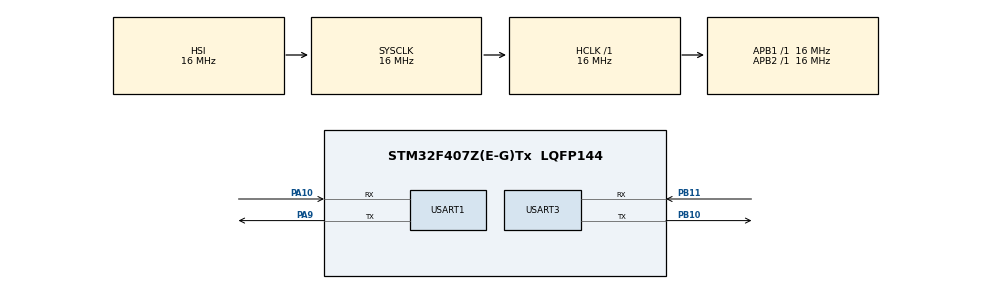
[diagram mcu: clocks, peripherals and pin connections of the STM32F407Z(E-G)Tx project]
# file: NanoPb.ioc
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Mcu.Family=STM32F4
Mcu.Name=STM32F407Z(E-G)Tx
Mcu.Package=LQFP144
NVIC.PriorityGroup=NVIC_PRIORITYGROUP_4
NVIC.TIM1_UP_TIM10_IRQn=true\:15\:0\:false\:false\:true\:false\:true\:true
NVIC.TimeBase=TIM1_UP_TIM10_IRQn
NVIC.TimeBaseIP=TIM1
PA10.Mode=Asynchronous
PA10.Signal=USART1_RX
PA13.Mode=JTAG_4_pins
PA13.Signal=SYS_JTMS-SWDIO
PA14.Mode=JTAG_4_pins
PA14.Signal=SYS_JTCK-SWCLK
PA15.Mode=JTAG_4_pins
PA15.Signal=SYS_JTDI
PA9.Mode=Asynchronous
PA9.Signal=USART1_TX
PB10.Mode=Asynchronous
PB10.Signal=USART3_TX
PB11.Mode=Asynchronous
PB11.Signal=USART3_RX
PB3.Mode=JTAG_4_pins
PB3.Signal=SYS_JTDO-SWO
PH0-OSC_IN.Mode=HSE-External-Oscillator
PH0-OSC_IN.Signal=RCC_OSC_IN
PH1-OSC_OUT.Mode=HSE-External-Oscillator
PH1-OSC_OUT.Signal=RCC_OSC_OUT
ProjectManager.HeapSize=0x2000
ProjectManager.StackSize=0x4000
ProjectManager.TargetToolchain=STM32CubeIDE
RCC.48MHZClocksFreq_Value=48000000
RCC.AHBFreq_Value=16000000
RCC.APB1Freq_Value=16000000
RCC.APB1TimCLKDivider=1
RCC.APB1TimFreq_Value=16000000
RCC.APB2Freq_Value=16000000
RCC.APB2TimCLKDivider=1
RCC.APB2TimFreq_Value=16000000
RCC.CortexFreq_Value=16000000
RCC.HCLKFreq_Value=16000000
RCC.HSE_VALUE=25000000
RCC.HSI_VALUE=16000000
RCC.LSE_VALUE=32768
RCC.SYSCLKFreq_VALUE=16000000
RCC.VCOOutputFreq_Value=192000000
USART1.VirtualMode=VM_ASYNC
USART3.VirtualMode=VM_ASYNC
VP_SYS_VS_tim1.Mode=TIM1
board=custom

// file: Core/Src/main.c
/* USER CODE BEGIN Header */
/**
  ******************************************************************************
  * @file           : main.c
  * @brief          : Main program body
  ******************************************************************************
  * @attention
  *
  * Copyright (c) 2024 STMicroelectronics.
  * All rights reserved.
  *
  * This software is licensed under terms that can be found in the LICENSE file
  * in the root directory of this software component.
  * If no LICENSE file comes with this software, it is provided AS-IS.
  *
  ******************************************************************************
  */
/* USER CODE END Header */
#include "main.h"

/* USER CODE BEGIN Includes */
#include <stdio.h>
#include <pb_encode.h>
#include <pb_decode.h>
#include "simple.pb.h"

/* USER CODE END Includes */

UART_HandleTypeDef huart1;
UART_HandleTypeDef huart3;

void SystemClock_Config(void);
static void MX_GPIO_Init(void);
static void MX_USART1_UART_Init(void);
static void MX_USART3_UART_Init(void);

/* USER CODE BEGIN 0 */
#ifdef __GNUC__
#define PUTCHAR_PROTOTYPE int __io_putchar(int ch)
#else
#define PUTCHAR_PROTOTYPE int fputc(int ch, FILE *f)
#endif

PUTCHAR_PROTOTYPE
{
  HAL_UART_Transmit(&huart3, (uint8_t *)&ch, 1, HAL_MAX_DELAY);
  return ch;
}
/* USER CODE END 0 */

int main(void)
{

  /* MCU Configuration--------------------------------------------------------*/

  /* Reset of all peripherals, Initializes the Flash interface and the Systick. */
  HAL_Init();

  /* Configure the system clock */
  SystemClock_Config();

  /* Initialize all configured peripherals */
  MX_GPIO_Init();
  MX_USART1_UART_Init();
  MX_USART3_UART_Init();

  /* Infinite loop */
  while (1)
  {
	  uint8_t buffer[128];

	      // uint8_t buffer2[128];
	      size_t message_length;
	      bool status;

	      /* Encode our message */
	      {
	          /* Allocate space on the stack to store the message data.
	           *
	           * Nanopb generates simple struct definitions for all the messages.
	           * - check out the contents of simple.pb.h!
	           * It is a good idea to always initialize your structures
	           * so that you do not have garbage data from RAM in there.
	           */
	          SimpleMessage message = SimpleMessage_init_zero;

	          /* Create a stream that will write to our buffer. */
	          pb_ostream_t stream = pb_ostream_from_buffer(buffer, sizeof(buffer));

	          /* Fill in the lucky number */
	          message.lucky_number = 13;

	          /* Now we are ready to encode the message! */
	          status = pb_encode(&stream, SimpleMessage_fields, &message);
	          message_length = stream.bytes_written;

	          /* Then just check for any errors.. */
	          if (!status)
	          {
	              printf("Encoding failed: %s\n", PB_GET_ERROR(&stream));
	              return 1;
	          }
	      }

	      /* Now we could transmit the message over network, store it in a file or
	       * wrap it to a pigeon's leg.
	       */

	      /* But because we are lazy, we will just decode it immediately. */

	      {
	          /* Allocate space for the decoded message. */
	          SimpleMessage message = SimpleMessage_init_zero;

	          /* Create a stream that reads from the buffer. */
	          pb_istream_t stream = pb_istream_from_buffer(buffer, message_length);

	          /* Now we are ready to decode the message. */
	          status = pb_decode(&stream, SimpleMessage_fields, &message);

	          /* Check for errors... */
	          if (!status)
	          {
	              printf("Decoding failed: %s\n", PB_GET_ERROR(&stream));
	              return 1;
	          }
	          printf("JHGGGFXGFCHGH\n");
	          /* Print the data contained in the message. */
	          printf("Your lucky number was %d!\n", (int)message.lucky_number);
	      }
	      HAL_Delay(1000);

  }
}

void SystemClock_Config(void)
{
  RCC_OscInitTypeDef RCC_OscInitStruct = {0};
  RCC_ClkInitTypeDef RCC_ClkInitStruct = {0};

  /** Configure the main internal regulator output voltage
  */
  __HAL_RCC_PWR_CLK_ENABLE();
  __HAL_PWR_VOLTAGESCALING_CONFIG(PWR_REGULATOR_VOLTAGE_SCALE1);

  /** Initializes the RCC Oscillators according to the specified parameters
  * in the RCC_OscInitTypeDef structure.
  */
  RCC_OscInitStruct.OscillatorType = RCC_OSCILLATORTYPE_HSI;
  RCC_OscInitStruct.HSIState = RCC_HSI_ON;
  RCC_OscInitStruct.HSICalibrationValue = RCC_HSICALIBRATION_DEFAULT;
  RCC_OscInitStruct.PLL.PLLState = RCC_PLL_NONE;
  if (HAL_RCC_OscConfig(&RCC_OscInitStruct) != HAL_OK)
  {
    Error_Handler();
  }

  /** Initializes the CPU, AHB and APB buses clocks
  */
  RCC_ClkInitStruct.ClockType = RCC_CLOCKTYPE_HCLK|RCC_CLOCKTYPE_SYSCLK
                              |RCC_CLOCKTYPE_PCLK1|RCC_CLOCKTYPE_PCLK2;
  RCC_ClkInitStruct.SYSCLKSource = RCC_SYSCLKSOURCE_HSI;
  RCC_ClkInitStruct.AHBCLKDivider = RCC_SYSCLK_DIV1;
  RCC_ClkInitStruct.APB1CLKDivider = RCC_HCLK_DIV1;
  RCC_ClkInitStruct.APB2CLKDivider = RCC_HCLK_DIV1;

  if (HAL_RCC_ClockConfig(&RCC_ClkInitStruct, FLASH_LATENCY_0) != HAL_OK)
  {
    Error_Handler();
  }
}

static void MX_USART1_UART_Init(void)
{

  huart1.Instance = USART1;
  huart1.Init.BaudRate = 115200;
  huart1.Init.WordLength = UART_WORDLENGTH_8B;
  huart1.Init.StopBits = UART_STOPBITS_1;
  huart1.Init.Parity = UART_PARITY_NONE;
  huart1.Init.Mode = UART_MODE_TX_RX;
  huart1.Init.HwFlowCtl = UART_HWCONTROL_NONE;
  huart1.Init.OverSampling = UART_OVERSAMPLING_16;
  if (HAL_UART_Init(&huart1) != HAL_OK)
  {
    Error_Handler();
  }

}

static void MX_USART3_UART_Init(void)
{

  huart3.Instance = USART3;
  huart3.Init.BaudRate = 115200;
  huart3.Init.WordLength = UART_WORDLENGTH_8B;
  huart3.Init.StopBits = UART_STOPBITS_1;
  huart3.Init.Parity = UART_PARITY_NONE;
  huart3.Init.Mode = UART_MODE_TX_RX;
  huart3.Init.HwFlowCtl = UART_HWCONTROL_NONE;
  huart3.Init.OverSampling = UART_OVERSAMPLING_16;
  if (HAL_UART_Init(&huart3) != HAL_OK)
  {
    Error_Handler();
  }

}

static void MX_GPIO_Init(void)
{

  /* GPIO Ports Clock Enable */
  __HAL_RCC_GPIOH_CLK_ENABLE();
  __HAL_RCC_GPIOB_CLK_ENABLE();
  __HAL_RCC_GPIOA_CLK_ENABLE();

}

void HAL_TIM_PeriodElapsedCallback(TIM_HandleTypeDef *htim)
{
  if (htim->Instance == TIM1) {
    HAL_IncTick();
  }
}

void Error_Handler(void)
{
  __disable_irq();
  while (1)
  {
  }
}
